# A31G12x_series register map
Vendor: ABOV Semiconductor Co., Ltd.; Series: A31G12x_series; File version: 1.0
CPU: CM0PLUS r0p1, little endian, no MPU, no FPU, VTOR, 2 interrupt priority bits
Registers are 32-bit, read-write, reset 0x0 unless marked. A register's access mark holds for its fields unless they carry their own. Offsets are from the block's base; [hi:lo] are bit positions; {n}, {i} and the like mark numbered series.

## I2C0
Base 0x40004800
Same registers: I2C1 0x40004900, I2C2 0x40004A00
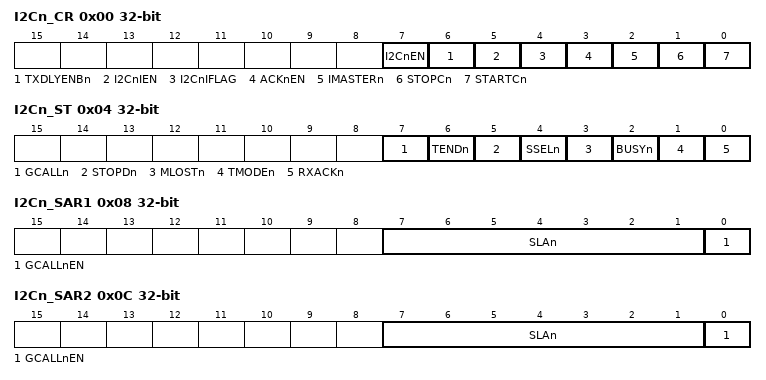
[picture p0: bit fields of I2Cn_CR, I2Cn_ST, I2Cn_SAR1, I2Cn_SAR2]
0x00 I2Cn_CR — I2Cn Control Register
  [7] I2CnEN — Activate I2Cn Block by supplying
  [6] TXDLYENBn — I2CnSDHR Register Control bit
  [5] I2CnIEN — I2Cn Interrupt Enable bit
  [4] I2CnIFLAG — I2Cn Interrupt Flag bit. This bit is cleared when write any values in the I2CnST register.
  [3] ACKnEN — Controls ACK signal generation at ninth SCL period. Notes) ACK signal is output (SDA = 0) for the following 3 cases. Where x = 0 and 1. 1. When received address packet equals to SLAx[6:0] bits in I2CnSARx register. 2. When received address packet equals to value 0x00 with GCALLn enabled. 3. When I2Cn operates as a receiver (master or slave)
  [2] IMASTERn ro — Represent Operation Mode of I2Cn
  [1] STOPCn — STOP Condition Generation When I2Cn is master.
  [0] STARTCn — START Condition Generation When I2Cn is master.
0x04 I2Cn_ST — I2Cn Status Register
  [7] GCALLn — This bit has different meaning depending on whether I2C is master or slave. When I2C is a master, this bit represents whether it received AACK (address ACK) from slave.
  [6] TENDn — This bit is set when 1-byte of data is transferred completely.
  [5] STOPDn — This bit is set when a STOP condition is detected.
  [4] SSELn — This bit is set when I2C is addressed by other master.
  [3] MLOSTn — This bit represents the result of bus arbitration in master mode.
  [2] BUSYn — This bit reflects bus status.
  [1] TMODEn ro — This bit is used to indicate whether I2C is transmitter or receiver.
  [0] RXACKn — This bit shows the state of ACK signal.
0x08 I2Cn_SAR1 — I2Cn Slave Address Register 1
  [7:1] SLAn — These bits configure the slave address 0 in slave mode.
  [0] GCALLnEN — This bit decides whether I2Cn allows general call address 0 or not in I2Cn slave mode.
0x0C I2Cn_SAR2 — I2Cn Slave Address Register 2
  [7:1] SLAn — These bits configure the slave address 1 in slave mode.
  [0] GCALLnEN — This bit decides whether I2Cn allows general call address 1 or not in I2Cn slave mode.
0x10 I2Cn_DR — I2Cn Data Register
  [7:0] DATA — The I2CnDR Transmit buffer and Receive buffer share the same I/O address with this DATA register. The Transmit Data Buffer is the destination for data written to the I2CnDR register. Reading the I2CnDR register returns the contents of the Receive Buffer.
0x14 I2Cn_SDHR reset 0x1 — I2Cn SDA Hold Time Register
  [11:0] HLDT — This register is used to control SDA output timing from the falling edge of SCL. Note that SDA is changed after tPCLK X (I2CnSDHR+2). In master mode, load half the value of I2CnSCLR to this register to make SDA change in the middle of SCL. In slave mode, configure this register regarding the frequency of SCL from master. The SDA is changed after tPCLK X (I2CnSDHR+2) in master mode. So, to insure operation in slave mode, the value tPCLK X (I2CnSDHR + 2) must be smaller than the period of SCL.
0x18 I2Cn_SCLR reset 0x3F — I2Cn SCL Low Period Register
  [11:0] SCLL — This register defines the low period of SCL in master mode. The base clock is PCLK and the period is calculated by the formula: tPCLK X (4 X I2CnSCLR + 2) where tPCLK is the period of PCLK.
0x1C I2Cn_SCHR reset 0x3F — I2Cn SCL High Period Register
  [11:0] SCLH — This register defines the high period of SCL in master mode. The base clock is PCLK and the period is calculated by the formula: tPCLK X (4 X I2CnSCHR + 2) where tPCLK is the period of PCLK.

## LCD — LCD DRIVER/CONTROLLER
Base 0x40005000
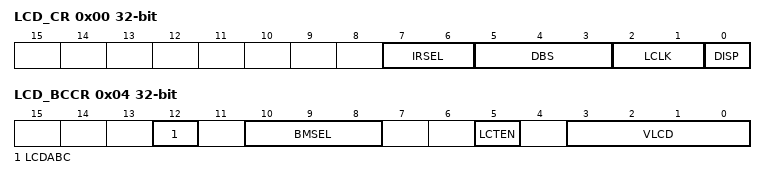
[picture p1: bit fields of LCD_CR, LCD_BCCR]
0x00 LCD_CR — LCD Driver Control Register
  [7:6] IRSEL — Internal LCD Bias Dividing Resistor Selection bits
    0=RLCD3 (RLCD3: 105/105/80[kohm] @(1/2)/(1/3)/(1/4) bias); 1=RLCD1 (RLCD1: 10/10/10[kohm] @(1/2)/(1/3)/(1/4) bias); 2=RLCD2 (RLCD2: 66/66/50[kohm] @(1/2)/(1/3)/(1/4) bias); 3=RLCD4 (RLCD4: 320/320/240[kohm] @(1/2)/(1/3)/(1/4) bias)
  [5:3] DBS — LCD Duty and Bias Selection bits
    0=DUTY8_BIAS4 (1/8 duty, 1/4 bias); 1=DUTY6_BIAS4 (1/6 duty, 1/4 bias); 2=DUTY5_BIAS3 (1/5 duty, 1/3 bias); 3=DUTY4_BIAS3 (1/4 duty, 1/3 bias); 4=DUTY3_BIAS3 (1/3 duty, 1/3 bias); 5=DUTY3_BIAS2 (1/3 duty, 1/2 bias)
  [2:1] LCLK — LCD Clock Selection bits (When fLCD = 32.768kHz)
    0=fLCD_128Hz (128Hz); 1=fLCD_256Hz (256Hz); 2=fLCD_512Hz (512Hz); 3=fLCD_1024Hz (1024Hz)
  [0] DISP — LCD Display Control bit
    0=DISPLAY_OFF; 1=DISPLAY_ON (Normal display on)
0x04 LCD_BCCR — LCD Automatic Bias and Contrast Control Register. Notes: 1. The above LCD contrast step is based on 1/3 bias with 66kohm RLCD and on 1/4 bias with 50kohm RLCD 2. The "LCD driver contrast control" is disabled during the LCDABC bit (LCD automatic bias) is set to "1b".
  [12] LCDABC — LCD Automatic Bias Control bit
    0=LCD_AUTO_BIAS_OFF (LCD automatic bias is off); 1=LCD_AUTO_BIAS_ON (LCD automatic bias is on)
  [10:8] BMSEL — "Bias Mode A" fsTime Selection bits
    {v}="Bias Mode A" for {v+1}-clock of fLCD (v=0..7)
  [5] LCTEN — LCD Driver Contrast Control bit
    0=Disable LCD driver contrast; 1=Enable LCD driver contrast
  [3:0] VLCD — VLC0 Voltage Control when the contrast is enabled
    0=VDD x 16/31 step; 1=VDD x 16/30 step; 2=VDD x 16/29 step; 3=VDD x 16/28 step; 4=VDD x 16/27 step; 5=VDD x 16/26 step; 6=VDD x 16/25 step; 7=VDD x 16/24 step; 8=VDD x 16/23 step; 9=VDD x 16/22 step; 10=VDD x 16/21 step; 11=VDD x 16/20 step; 12=VDD x 16/19 step; 13=VDD x 16/18 step; 14=VDD x 16/17 step; 15=VDD x 16/16 step
{0x10+i} LCD_DR{i} 8-bit (i=0..43) — LCD Display Data Register {i}
